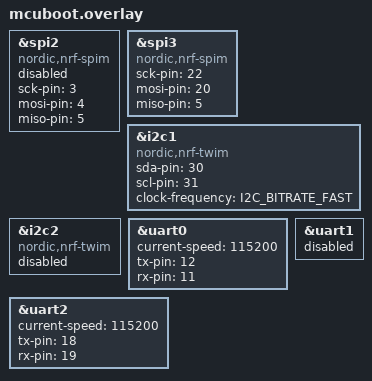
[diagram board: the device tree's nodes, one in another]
&spi2{
	compatible = "nordic,nrf-spim";
	status = "disabled";
	sck-pin = <3>;
	mosi-pin = <4>;
	miso-pin = <5>;
};

&spi3{
	compatible = "nordic,nrf-spim";
	status = "okay";
	sck-pin = <22>;
	mosi-pin = <20>;
	miso-pin = <5>;
};

&i2c1{
	compatible = "nordic,nrf-twim";
	status = "okay";
	sda-pin = <30>;
	scl-pin = <31>;
	clock-frequency = <I2C_BITRATE_FAST>;
};

&i2c2{
	compatible = "nordic,nrf-twim";
	status = "disabled";
};

&uart0 {
	status = "okay";
	current-speed = <115200>;
	tx-pin = <12>;
	rx-pin = <11>;
	/* delete rts-pin&cts-pin to release the related 2 pins for other uses */
	/delete-property/ rts-pin;
	/delete-property/ cts-pin;	
};

&uart1{
	status = "disabled";
};

&uart2{
	status = "okay";
	current-speed = <115200>;
	tx-pin = <18>;
	rx-pin = <19>;
	/* delete rts-pin&cts-pin to release the related 2 pins for other uses */
	/delete-property/ rts-pin;
	/delete-property/ cts-pin;
};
